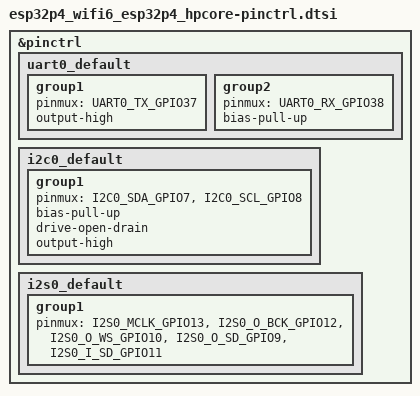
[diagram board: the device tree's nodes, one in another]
/*
 * Copyright (c) 2026 Hongquan Li
 *
 * SPDX-License-Identifier: Apache-2.0
 */

#include <zephyr/dt-bindings/pinctrl/esp-pinctrl-common.h>
#include <zephyr/dt-bindings/pinctrl/esp32p4-pinctrl.h>
#include <zephyr/dt-bindings/pinctrl/esp32p4-gpio-sigmap.h>

&pinctrl {
	uart0_default: uart0_default {
		group1 {
			pinmux = <UART0_TX_GPIO37>;
			output-high;
		};

		group2 {
			pinmux = <UART0_RX_GPIO38>;
			bias-pull-up;
		};
	};

	i2c0_default: i2c0_default {
		group1 {
			pinmux = <I2C0_SDA_GPIO7>,
				 <I2C0_SCL_GPIO8>;
			bias-pull-up;
			drive-open-drain;
			output-high;
		};
	};

	i2s0_default: i2s0_default {
		group1 {
			pinmux = <I2S0_MCLK_GPIO13>,
				 <I2S0_O_BCK_GPIO12>,
				 <I2S0_O_WS_GPIO10>,
				 <I2S0_O_SD_GPIO9>,
				 <I2S0_I_SD_GPIO11>;
		};
	};
};
